# CY8C3866LTI_030 register map
File version: 0.1
Registers are 8-bit, read-write, no defined reset value unless marked. A register's access mark holds for its fields unless they carry their own. Offsets are from the block's base; [hi:lo] are bit positions; 'fields as' and 'values as' point back to an identical list.

## DEBUG_UART — UART
Base 0x00000000
0x654A TX_DEBUG_UART_TX_DATA — TX Data Register
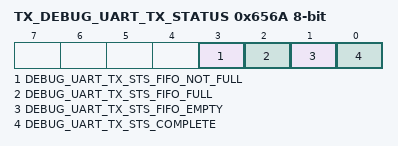
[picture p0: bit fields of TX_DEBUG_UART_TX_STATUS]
0x656A TX_DEBUG_UART_TX_STATUS — TX status register
  [3] DEBUG_UART_TX_STS_FIFO_NOT_FULL ro, [2] DEBUG_UART_TX_STS_FIFO_FULL ro, [1] DEBUG_UART_TX_STS_FIFO_EMPTY ro, [0] DEBUG_UART_TX_STS_COMPLETE ro

## RTC
Base 0x00000000
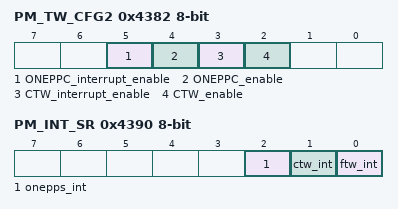
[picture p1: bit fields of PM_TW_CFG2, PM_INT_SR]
0x4382 PM_TW_CFG2 — Power timers enable and interrupt enable configuration register
  [5] ONEPPC_interrupt_enable — When set and one pulse-per-second is enabled, an interrupt is issued when the pulse occurs
    1=Enabled (The ONEPPC interrupt is issued. Only if ONEPPC is enabled.); 0=Disabled (No ONEPPC interrupt is issued.)
  [4] ONEPPC_enable
    1=Enabled (The ONEPPC is enabled.); 0=Disabled (The ONEPPC is disabled.)
  [3] CTW_interrupt_enable — An interrupt issue when the CTW reaches the selected interval
    1=Enabled (The CTW interrupt is issued. Only if CTW is enabled.); 0=Disabled (No CTW interrupt is issued.)
  [2] CTW_enable
    1=Enabled (The CTW is enabled.); 0=Disabled (The CTW is disabled.)
0x4390 PM_INT_SR — Power Manager Interrupt Status Register
  [2] onepps_int — When set, a onepps event has occured.
  [1] ctw_int — When set, a limited active ready event has occured
  [0] ftw_int — When set, a fast timewheel event has occured

## Tick_Timer
Base 0x00000000
0x6504 Tick_Timer_COUNTER 24-bit — UDB.A0 - Current Down Counter Value
0x6524 Tick_Timer_PERIOD 24-bit — UDB.D0 - Assigned Period
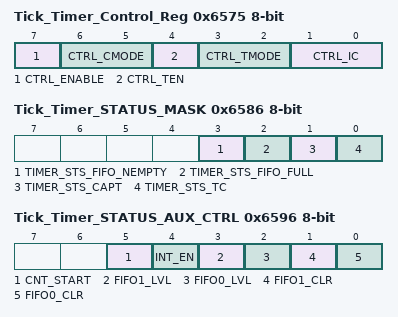
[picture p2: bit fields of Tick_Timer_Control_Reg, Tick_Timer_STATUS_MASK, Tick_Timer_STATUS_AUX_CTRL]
0x6575 Tick_Timer_Control_Reg — UDB Control Register - Assigned Control Register Value
  [7] CTRL_ENABLE — Enable the Timer
  [6:5] CTRL_CMODE — Capture Mode
  [4] CTRL_TEN — Trigger Enable Bit
  [3:2] CTRL_TMODE — Trigger Mode
  [1:0] CTRL_IC — Interrupt Count
0x6586 Tick_Timer_STATUS_MASK — UDB Status bits Interrupt Mask Enable Register
  [3] TIMER_STS_FIFO_NEMPTY ro — FIFO Empty status
  [2] TIMER_STS_FIFO_FULL ro — FIFO Full Status
  [1] TIMER_STS_CAPT ro — Enables the Interrupt on Capture
  [0] TIMER_STS_TC ro — Enables the Interrupt on TC
0x6596 Tick_Timer_STATUS_AUX_CTRL — UDB Auxilliary Control Register
  [5] CNT_START — FIFO0 clear
    0=E_CNT_START0 (Disable counter); 1=E_CNT_START1 (Enable counter)
  [4] INT_EN
    0=E_INT_EN0 (Interrupt disabled); 1=E_INT_EN1 (Interrupt enabled)
  [3] FIFO1_LVL — FIFO level
    0=E_FIFO_LVL_0 (FIFO LVL: input mode: FIFO not full; output mode: FIFO not empty); 1=E_FIFO_LVL_1 (FIFO LVL: input mode: FIFO at least 1/2 empty; output mode: FIFO at least 1/2 full)
  [2] FIFO0_LVL — FIFO level
    values as FIFO1_LVL
  [1] FIFO1_CLR — FIFO1 clear
    0=E_FIFO_CLR_0 (Normal FIFO operation); 1=E_FIFO_CLR_1 (Clear FIFO state)
  [0] FIFO0_CLR — FIFO0 clear
    values as FIFO1_CLR

## Timer_1
Base 0x00000000
0x6404 Timer_1_COUNTER 24-bit — UDB.A0 - Current Down Counter Value
0x6424 Timer_1_PERIOD 24-bit — UDB.D0 - Assigned Period
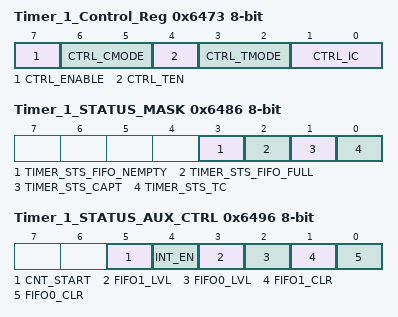
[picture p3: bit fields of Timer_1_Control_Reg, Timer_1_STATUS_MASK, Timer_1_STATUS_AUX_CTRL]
0x6473 Timer_1_Control_Reg — UDB Control Register - Assigned Control Register Value
  [7] CTRL_ENABLE — Enable the Timer
  [6:5] CTRL_CMODE — Capture Mode
  [4] CTRL_TEN — Trigger Enable Bit
  [3:2] CTRL_TMODE — Trigger Mode
  [1:0] CTRL_IC — Interrupt Count
0x6486 Timer_1_STATUS_MASK — UDB Status bits Interrupt Mask Enable Register
  [3] TIMER_STS_FIFO_NEMPTY ro — FIFO Empty status
  [2] TIMER_STS_FIFO_FULL ro — FIFO Full Status
  [1] TIMER_STS_CAPT ro — Enables the Interrupt on Capture
  [0] TIMER_STS_TC ro — Enables the Interrupt on TC
0x6496 Timer_1_STATUS_AUX_CTRL — UDB Auxilliary Control Register
  [5] CNT_START — FIFO0 clear
    0=E_CNT_START0 (Disable counter); 1=E_CNT_START1 (Enable counter)
  [4] INT_EN
    0=E_INT_EN0 (Interrupt disabled); 1=E_INT_EN1 (Interrupt enabled)
  [3] FIFO1_LVL — FIFO level
    0=E_FIFO_LVL_0 (FIFO LVL: input mode: FIFO not full; output mode: FIFO not empty); 1=E_FIFO_LVL_1 (FIFO LVL: input mode: FIFO at least 1/2 empty; output mode: FIFO at least 1/2 full)
  [2] FIFO0_LVL — FIFO level
    values as FIFO1_LVL
  [1] FIFO1_CLR — FIFO1 clear
    0=E_FIFO_CLR_0 (Normal FIFO operation); 1=E_FIFO_CLR_1 (Clear FIFO state)
  [0] FIFO0_CLR — FIFO0 clear
    values as FIFO1_CLR

## COMM_UART — UART
Base 0x00000000
0x6428 RX_COMM_UART_RX_ADDRESS1 — RX Address1 Register
0x6438 RX_COMM_UART_RX_ADDRESS2 — RX Address2 Register
0x6448 RX_COMM_UART_RX_DATA — RX Data Register
0x654B TX_COMM_UART_TX_DATA — TX Data Register
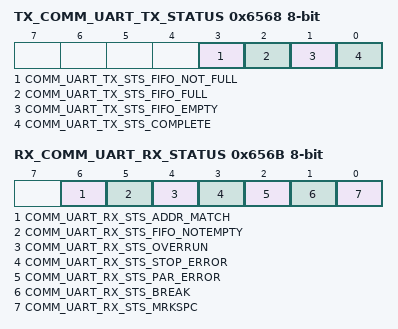
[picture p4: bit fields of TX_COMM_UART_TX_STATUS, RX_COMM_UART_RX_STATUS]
0x6568 TX_COMM_UART_TX_STATUS — TX status register
  [3] COMM_UART_TX_STS_FIFO_NOT_FULL ro, [2] COMM_UART_TX_STS_FIFO_FULL ro, [1] COMM_UART_TX_STS_FIFO_EMPTY ro, [0] COMM_UART_TX_STS_COMPLETE ro
0x656B RX_COMM_UART_RX_STATUS — RX status register
  [6] COMM_UART_RX_STS_ADDR_MATCH ro, [5] COMM_UART_RX_STS_FIFO_NOTEMPTY ro, [4] COMM_UART_RX_STS_OVERRUN ro, [3] COMM_UART_RX_STS_STOP_ERROR ro, [2] COMM_UART_RX_STS_PAR_ERROR ro, [1] COMM_UART_RX_STS_BREAK ro, [0] COMM_UART_RX_STS_MRKSPC ro
